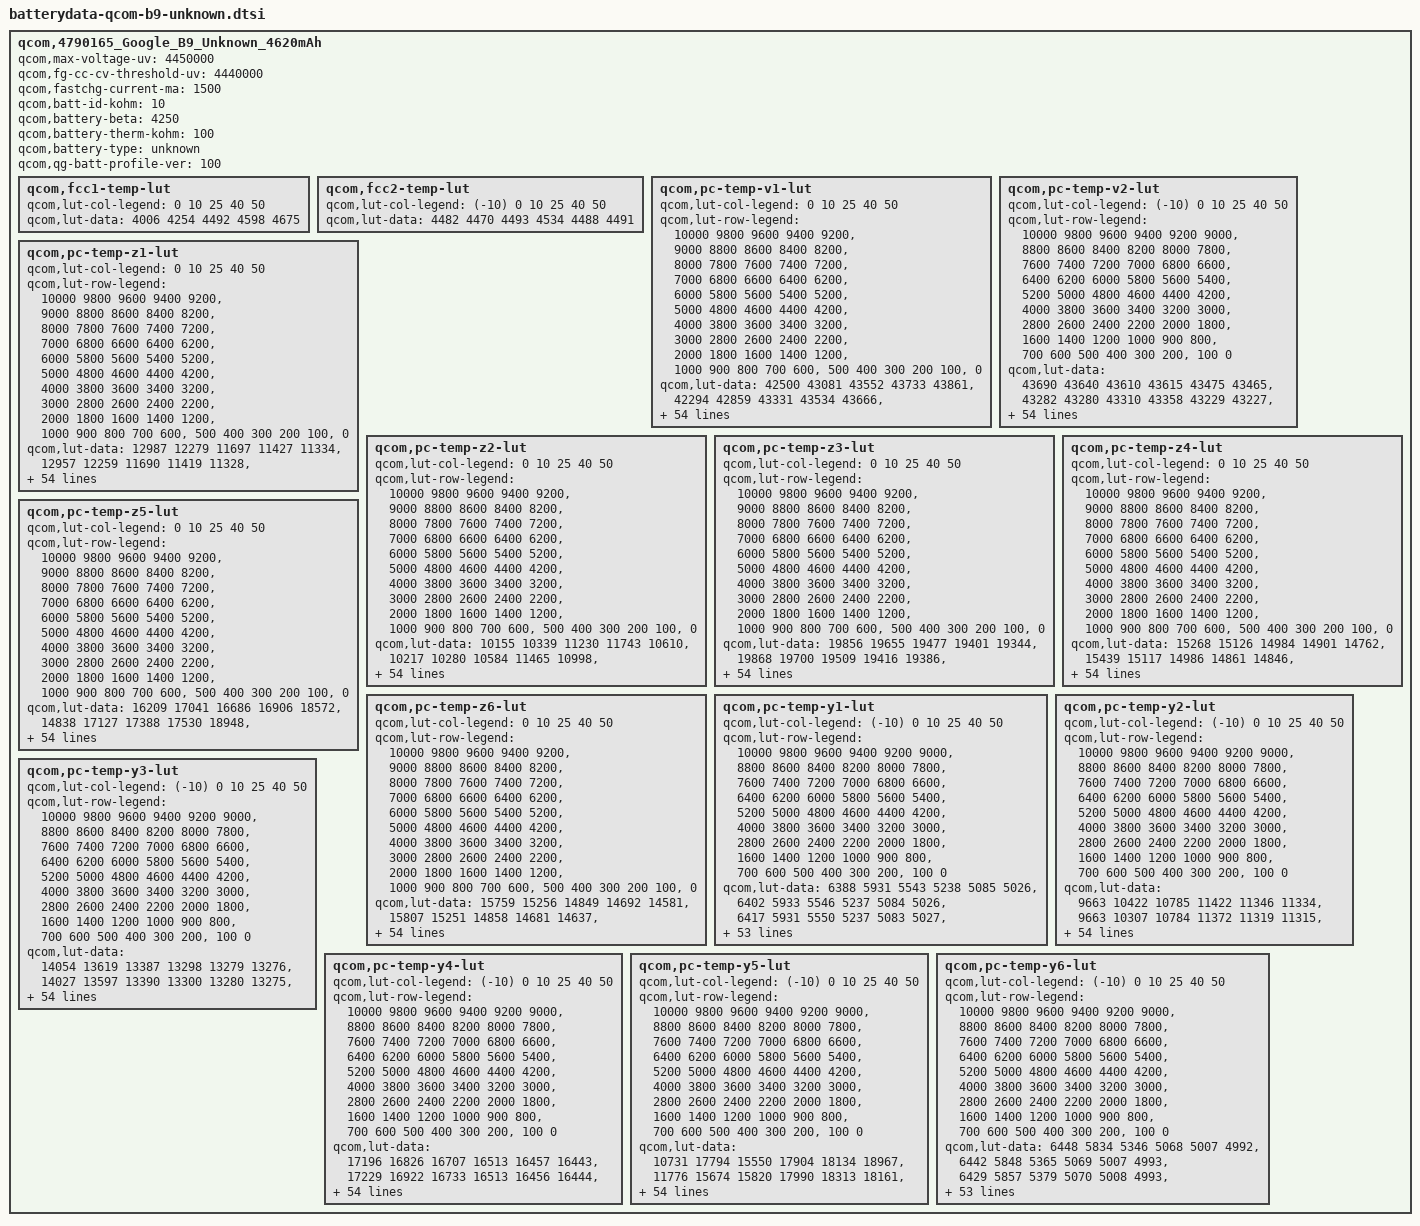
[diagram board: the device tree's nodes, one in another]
// SPDX-License-Identifier: GPL-2.0
qcom,4790165_Google_B9_Unknown_4620mAh {
	/* 4790165_Google_B9lwn_4620mAh_averaged_MasterSlave_Sept25th2020 */
	qcom,max-voltage-uv = <4450000>;
	qcom,fg-cc-cv-threshold-uv = <4440000>;
	qcom,fastchg-current-ma = <1500>;
	qcom,batt-id-kohm = <10>;
	qcom,battery-beta = <4250>;
	qcom,battery-therm-kohm = <100>;
	qcom,battery-type = "unknown";
	qcom,qg-batt-profile-ver = <100>;

	qcom,fcc1-temp-lut {
		qcom,lut-col-legend = <0 10 25 40 50>;
		qcom,lut-data = <4006 4254 4492 4598 4675>;
	};

	qcom,fcc2-temp-lut {
		qcom,lut-col-legend = <(-10) 0 10 25 40 50>;
		qcom,lut-data = <4482 4470 4493 4534 4488 4491>;
	};

	qcom,pc-temp-v1-lut {
		qcom,lut-col-legend = <0 10 25 40 50>;
		qcom,lut-row-legend = <10000 9800 9600 9400 9200>,
			<9000 8800 8600 8400 8200>,
			<8000 7800 7600 7400 7200>,
			<7000 6800 6600 6400 6200>,
			<6000 5800 5600 5400 5200>,
			<5000 4800 4600 4400 4200>,
			<4000 3800 3600 3400 3200>,
			<3000 2800 2600 2400 2200>,
			<2000 1800 1600 1400 1200>,
			<1000 900 800 700 600>,
			<500 400 300 200 100>,
			<0>;
		qcom,lut-data = <42500 43081 43552 43733 43861>,
			<42294 42859 43331 43534 43666>,
			<42088 42638 43108 43326 43467>,
			<41884 42419 42883 43106 43261>,
			<41683 42201 42656 42877 43040>,
			<41486 41985 42426 42646 42808>,
			<41294 41770 42196 42414 42576>,
			<41107 41562 41972 42182 42343>,
			<40927 41360 41752 41952 42111>,
			<40752 41162 41535 41722 41880>,
			<40577 40971 41319 41498 41651>,
			<40395 40786 41108 41281 41427>,
			<40221 40605 40907 41068 41204>,
			<40065 40424 40713 40862 40989>,
			<39926 40247 40527 40661 40781>,
			<39796 40084 40349 40468 40581>,
			<39669 39943 40177 40286 40389>,
			<39549 39803 40007 40109 40206>,
			<39428 39637 39847 39938 40026>,
			<39302 39446 39670 39773 39854>,
			<39172 39255 39425 39590 39680>,
			<39040 39063 39138 39347 39469>,
			<38905 38873 38957 39106 39225>,
			<38767 38743 38862 38947 39026>,
			<38652 38669 38785 38831 38885>,
			<38569 38613 38697 38726 38767>,
			<38500 38558 38607 38622 38656>,
			<38447 38506 38523 38526 38555>,
			<38409 38456 38445 38437 38461>,
			<38377 38407 38374 38354 38371>,
			<38348 38358 38313 38280 38288>,
			<38319 38313 38259 38215 38214>,
			<38292 38275 38210 38156 38146>,
			<38266 38240 38166 38100 38082>,
			<38243 38203 38126 38051 38027>,
			<38217 38169 38085 38000 37970>,
			<38182 38129 38046 37947 37903>,
			<38126 38069 37999 37889 37829>,
			<38050 37977 37925 37816 37748>,
			<37958 37869 37824 37724 37660>,
			<37829 37756 37713 37621 37562>,
			<37689 37628 37592 37505 37447>,
			<37538 37481 37455 37374 37315>,
			<37390 37328 37292 37214 37156>,
			<37272 37207 37164 37087 37025>,
			<37194 37165 37089 37015 36953>,
			<37164 37135 37070 36994 36933>,
			<37137 37110 37051 36982 36919>,
			<37100 37080 37031 36962 36900>,
			<36970 36984 36965 36899 36835>,
			<36659 36700 36688 36611 36546>,
			<36206 36247 36248 36175 36112>,
			<35635 35678 35689 35612 35548>,
			<34872 34910 34929 34848 34784>,
			<33589 33677 33743 33678 33618>,
			<30000 30000 30000 30000 30000>;
	};

	qcom,pc-temp-v2-lut {
		qcom,lut-col-legend = <(-10) 0 10 25 40 50>;
		qcom,lut-row-legend = <10000 9800 9600 9400 9200 9000>,
			<8800 8600 8400 8200 8000 7800>,
			<7600 7400 7200 7000 6800 6600>,
			<6400 6200 6000 5800 5600 5400>,
			<5200 5000 4800 4600 4400 4200>,
			<4000 3800 3600 3400 3200 3000>,
			<2800 2600 2400 2200 2000 1800>,
			<1600 1400 1200 1000 900 800>,
			<700 600 500 400 300 200>,
			<100 0>;
		qcom,lut-data = <43690 43640 43610 43615 43475 43465>,
			<43282 43280 43310 43358 43229 43227>,
			<42909 42951 43029 43108 42989 42993>,
			<42575 42656 42765 42867 42754 42762>,
			<42278 42389 42522 42635 42527 42536>,
			<42001 42145 42286 42405 42302 42312>,
			<41709 41925 42046 42174 42076 42087>,
			<41430 41721 41807 41945 41852 41864>,
			<41260 41509 41577 41720 41631 41644>,
			<41183 41282 41352 41498 41414 41427>,
			<41104 41055 41137 41280 41200 41214>,
			<40861 40843 40942 41068 40992 41006>,
			<40383 40642 40764 40861 40789 40802>,
			<40002 40430 40580 40661 40594 40606>,
			<39796 40192 40387 40466 40404 40415>,
			<39624 39945 40185 40277 40220 40231>,
			<39428 39704 39962 40099 40046 40057>,
			<39217 39465 39714 39929 39884 39894>,
			<39018 39237 39477 39740 39705 39716>,
			<38835 39022 39260 39506 39475 39489>,
			<38668 38819 39057 39265 39226 39245>,
			<38541 38636 38877 39065 39029 39050>,
			<38442 38461 38718 38887 38871 38891>,
			<38358 38319 38572 38734 38734 38753>,
			<38283 38233 38434 38610 38615 38633>,
			<38215 38169 38305 38500 38510 38527>,
			<38151 38114 38189 38397 38413 38428>,
			<38088 38062 38078 38300 38323 38334>,
			<38027 38014 37990 38211 38240 38248>,
			<37967 37968 37938 38129 38164 38169>,
			<37910 37925 37902 38055 38094 38097>,
			<37852 37880 37865 37986 38025 38027>,
			<37793 37834 37823 37924 37960 37965>,
			<37731 37785 37778 37863 37894 37900>,
			<37666 37733 37731 37802 37816 37813>,
			<37597 37679 37682 37740 37724 37699>,
			<37526 37619 37627 37674 37632 37588>,
			<37448 37552 37562 37604 37545 37495>,
			<37367 37475 37486 37528 37459 37407>,
			<37289 37389 37395 37446 37372 37319>,
			<37215 37287 37283 37357 37286 37233>,
			<37141 37177 37166 37252 37191 37139>,
			<37072 37061 37057 37119 37064 37011>,
			<37003 36943 36953 36993 36935 36885>,
			<36925 36853 36856 36890 36867 36821>,
			<36832 36781 36760 36841 36830 36784>,
			<36774 36749 36708 36825 36819 36771>,
			<36706 36713 36654 36806 36804 36756>,
			<36615 36657 36586 36767 36767 36721>,
			<36473 36561 36479 36662 36651 36592>,
			<36240 36345 36280 36341 36320 36250>,
			<35857 35920 35891 35848 35839 35769>,
			<35280 35302 35298 35203 35224 35148>,
			<34439 34440 34481 34308 34376 34298>,
			<33091 33099 33202 32966 33115 33027>,
			<29798 29527 29510 29513 29512 29525>;
	};

	qcom,pc-temp-z1-lut {
		qcom,lut-col-legend = <0 10 25 40 50>;
		qcom,lut-row-legend = <10000 9800 9600 9400 9200>,
			<9000 8800 8600 8400 8200>,
			<8000 7800 7600 7400 7200>,
			<7000 6800 6600 6400 6200>,
			<6000 5800 5600 5400 5200>,
			<5000 4800 4600 4400 4200>,
			<4000 3800 3600 3400 3200>,
			<3000 2800 2600 2400 2200>,
			<2000 1800 1600 1400 1200>,
			<1000 900 800 700 600>,
			<500 400 300 200 100>,
			<0>;
		qcom,lut-data = <12987 12279 11697 11427 11334>,
			<12957 12259 11690 11419 11328>,
			<12955 12253 11684 11412 11324>,
			<12950 12245 11679 11407 11321>,
			<12946 12240 11674 11403 11317>,
			<12933 12235 11670 11400 11314>,
			<12915 12229 11666 11398 11312>,
			<12907 12230 11663 11395 11310>,
			<12903 12243 11660 11393 11309>,
			<12899 12255 11658 11391 11308>,
			<12900 12252 11657 11390 11307>,
			<12916 12240 11656 11390 11307>,
			<12932 12232 11657 11389 11307>,
			<12933 12230 11661 11389 11307>,
			<12921 12229 11664 11390 11308>,
			<12910 12228 11663 11390 11309>,
			<12909 12229 11661 11391 11311>,
			<12907 12230 11661 11393 11312>,
			<12905 12231 11662 11394 11314>,
			<12906 12236 11665 11395 11316>,
			<12914 12242 11669 11397 11318>,
			<12920 12247 11677 11400 11320>,
			<12918 12253 11682 11404 11323>,
			<12913 12259 11686 11409 11327>,
			<12910 12265 11689 11414 11330>,
			<12914 12272 11692 11418 11334>,
			<12920 12277 11695 11423 11337>,
			<12927 12285 11698 11426 11340>,
			<12936 12291 11700 11430 11343>,
			<12948 12289 11703 11432 11346>,
			<12954 12280 11704 11435 11349>,
			<12952 12275 11705 11438 11352>,
			<12949 12280 11706 11442 11354>,
			<12949 12290 11711 11445 11356>,
			<12952 12298 11717 11448 11360>,
			<12955 12305 11720 11450 11363>,
			<12959 12311 11725 11453 11367>,
			<12964 12316 11728 11457 11370>,
			<12971 12320 11729 11460 11373>,
			<12982 12323 11732 11465 11375>,
			<13002 12325 11734 11468 11377>,
			<13010 12326 11737 11472 11381>,
			<12996 12335 11741 11475 11384>,
			<13006 12345 11752 11477 11386>,
			<13013 12328 11752 11482 11388>,
			<13024 12337 11763 11481 11389>,
			<12993 12334 11763 11482 11389>,
			<12977 12332 11765 11481 11389>,
			<12992 12338 11767 11486 11392>,
			<12995 12349 11767 11488 11393>,
			<13041 12362 11773 11493 11400>,
			<13047 12379 11780 11500 11405>,
			<13045 12393 11804 11511 11413>,
			<13078 12427 11826 11525 11424>,
			<13078 12427 11826 11525 11424>,
			<13078 12427 11826 11525 11424>;
	};

	qcom,pc-temp-z2-lut {
		qcom,lut-col-legend = <0 10 25 40 50>;
		qcom,lut-row-legend = <10000 9800 9600 9400 9200>,
			<9000 8800 8600 8400 8200>,
			<8000 7800 7600 7400 7200>,
			<7000 6800 6600 6400 6200>,
			<6000 5800 5600 5400 5200>,
			<5000 4800 4600 4400 4200>,
			<4000 3800 3600 3400 3200>,
			<3000 2800 2600 2400 2200>,
			<2000 1800 1600 1400 1200>,
			<1000 900 800 700 600>,
			<500 400 300 200 100>,
			<0>;
		qcom,lut-data = <10155 10339 11230 11743 10610>,
			<10217 10280 10584 11465 10998>,
			<10211 10251 10518 11289 11357>,
			<10198 10232 10485 11250 11516>,
			<10186 10225 10478 11236 11514>,
			<10174 10233 10493 11215 11514>,
			<10164 10247 10520 11171 11492>,
			<10158 10259 10596 11135 11382>,
			<10158 10271 10750 11139 11278>,
			<10158 10285 10832 11158 11228>,
			<10155 10301 10852 11165 11196>,
			<10141 10321 10862 11109 11206>,
			<10127 10337 10863 11045 11234>,
			<10126 10350 10853 11045 11244>,
			<10141 10362 10849 11072 10952>,
			<10161 10374 10864 11099 10619>,
			<10174 10387 10886 11130 10595>,
			<10186 10400 10871 11151 10604>,
			<10196 10409 10734 11049 10614>,
			<10205 10418 10626 10736 10629>,
			<10214 10422 10622 10596 10646>,
			<10222 10413 10614 10603 10659>,
			<10229 10391 10611 10617 10672>,
			<10235 10381 10618 10674 10690>,
			<10242 10386 10630 10837 10753>,
			<10251 10394 10647 10922 10817>,
			<10261 10401 10672 10820 10760>,
			<10270 10408 10682 10687 10573>,
			<10277 10415 10644 10662 10495>,
			<10284 10420 10595 10658 10495>,
			<10290 10425 10590 10658 10497>,
			<10298 10431 10604 10673 10513>,
			<10306 10439 10622 10700 10555>,
			<10303 10448 10647 10729 10603>,
			<10210 10457 10677 10784 10661>,
			<10100 10467 10702 10829 10719>,
			<10070 10478 10722 10871 10764>,
			<10019 10493 10742 10918 10804>,
			<9963 10513 10774 10953 10835>,
			<9962 10526 10809 10988 10880>,
			<10008 10524 10822 11004 10911>,
			<10012 10519 10818 10977 10883>,
			<9958 10522 10812 10949 10848>,
			<9902 10537 10796 10964 10904>,
			<9900 10660 10818 10928 10872>,
			<9914 11695 10831 10888 10823>,
			<10007 13597 10804 10796 10815>,
			<9902 13310 10796 10818 10793>,
			<9867 16744 10819 10788 10845>,
			<9785 19310 10868 10914 10984>,
			<9717 16266 10976 10890 10714>,
			<9612 13406 10908 10776 10605>,
			<9492 14788 11018 10722 10541>,
			<9380 10829 10954 10649 10484>,
			<9380 10829 10954 10649 10484>,
			<9380 10829 10954 10649 10484>;
	};

	qcom,pc-temp-z3-lut {
		qcom,lut-col-legend = <0 10 25 40 50>;
		qcom,lut-row-legend = <10000 9800 9600 9400 9200>,
			<9000 8800 8600 8400 8200>,
			<8000 7800 7600 7400 7200>,
			<7000 6800 6600 6400 6200>,
			<6000 5800 5600 5400 5200>,
			<5000 4800 4600 4400 4200>,
			<4000 3800 3600 3400 3200>,
			<3000 2800 2600 2400 2200>,
			<2000 1800 1600 1400 1200>,
			<1000 900 800 700 600>,
			<500 400 300 200 100>,
			<0>;
		qcom,lut-data = <19856 19655 19477 19401 19344>,
			<19868 19700 19509 19416 19386>,
			<19868 19700 19510 19425 19398>,
			<19863 19695 19510 19427 19402>,
			<19860 19688 19510 19427 19401>,
			<19861 19679 19499 19425 19399>,
			<19863 19668 19486 19418 19396>,
			<19861 19657 19482 19410 19387>,
			<19851 19644 19482 19407 19379>,
			<19839 19632 19480 19406 19372>,
			<19837 19626 19478 19403 19367>,
			<19850 19622 19475 19394 19365>,
			<19864 19617 19469 19384 19364>,
			<19864 19611 19458 19380 19362>,
			<19835 19604 19449 19377 19350>,
			<19805 19598 19446 19375 19337>,
			<19797 19591 19444 19373 19334>,
			<19793 19586 19442 19371 19332>,
			<19792 19590 19440 19366 19332>,
			<19795 19608 19440 19357 19334>,
			<19807 19623 19447 19354 19336>,
			<19818 19624 19460 19354 19335>,
			<19824 19625 19464 19354 19330>,
			<19829 19626 19447 19358 19328>,
			<19831 19621 19429 19371 19350>,
			<19830 19614 19435 19382 19375>,
			<19827 19609 19458 19389 19374>,
			<19824 19606 19473 19394 19364>,
			<19816 19604 19478 19394 19358>,
			<19804 19605 19480 19393 19357>,
			<19793 19608 19479 19390 19355>,
			<19782 19610 19471 19386 19353>,
			<19771 19608 19463 19380 19350>,
			<19751 19604 19457 19375 19346>,
			<19647 19600 19452 19371 19340>,
			<19529 19595 19448 19368 19336>,
			<19487 19591 19445 19367 19337>,
			<19387 19587 19442 19366 19339>,
			<19282 19582 19440 19365 19339>,
			<19262 19578 19437 19365 19339>,
			<19262 19573 19434 19364 19339>,
			<19262 19568 19430 19361 19337>,
			<19262 19560 19426 19357 19333>,
			<19262 19547 19421 19359 19338>,
			<19262 19507 19409 19354 19338>,
			<19262 19258 19404 19346 19329>,
			<19262 19257 19396 19344 19325>,
			<19262 19257 19396 19336 19322>,
			<19263 19257 19382 19336 19319>,
			<19263 19256 19381 19327 19319>,
			<19264 19257 19373 19332 19336>,
			<19266 19257 19372 19343 19339>,
			<19269 19257 19336 19340 19343>,
			<19273 19259 19328 19347 19346>,
			<19273 19259 19328 19347 19346>,
			<19273 19259 19328 19347 19346>;
	};

	qcom,pc-temp-z4-lut {
		qcom,lut-col-legend = <0 10 25 40 50>;
		qcom,lut-row-legend = <10000 9800 9600 9400 9200>,
			<9000 8800 8600 8400 8200>,
			<8000 7800 7600 7400 7200>,
			<7000 6800 6600 6400 6200>,
			<6000 5800 5600 5400 5200>,
			<5000 4800 4600 4400 4200>,
			<4000 3800 3600 3400 3200>,
			<3000 2800 2600 2400 2200>,
			<2000 1800 1600 1400 1200>,
			<1000 900 800 700 600>,
			<500 400 300 200 100>,
			<0>;
		qcom,lut-data = <15268 15126 14984 14901 14762>,
			<15439 15117 14986 14861 14846>,
			<15395 15080 14955 14826 14807>,
			<15299 15010 14898 14796 14768>,
			<15214 14952 14860 14769 14747>,
			<15149 14910 14840 14753 14731>,
			<15091 14877 14824 14744 14723>,
			<15043 14859 14804 14738 14719>,
			<15003 14850 14780 14728 14716>,
			<14970 14843 14763 14716 14710>,
			<14945 14831 14750 14708 14703>,
			<14921 14817 14740 14704 14694>,
			<14904 14810 14736 14701 14684>,
			<14901 14812 14734 14695 14678>,
			<14904 14815 14732 14687 14682>,
			<14908 14815 14726 14679 14686>,
			<14904 14799 14717 14671 14682>,
			<14885 14781 14715 14666 14674>,
			<14867 14784 14722 14668 14670>,
			<14863 14812 14734 14682 14672>,
			<14862 14850 14798 14703 14677>,
			<14863 14905 14923 14784 14708>,
			<14881 14976 14968 14874 14801>,
			<14924 15006 14955 14878 14845>,
			<14952 14987 14933 14845 14808>,
			<14953 14956 14901 14812 14761>,
			<14953 14929 14854 14784 14745>,
			<14950 14903 14819 14759 14737>,
			<14939 14880 14797 14741 14728>,
			<14919 14862 14782 14727 14715>,
			<14901 14846 14776 14718 14703>,
			<14885 14834 14773 14711 14693>,
			<14871 14826 14771 14706 14686>,
			<14870 14820 14772 14706 14683>,
			<14955 14814 14773 14709 14686>,
			<15057 14809 14774 14713 14690>,
			<15091 14805 14775 14721 14700>,
			<15178 14805 14776 14731 14716>,
			<15271 14809 14780 14737 14720>,
			<15283 14812 14787 14742 14720>,
			<15277 14805 14788 14744 14719>,
			<15268 14789 14774 14736 14715>,
			<15246 14780 14762 14730 14710>,
			<15180 14770 14757 14729 14711>,
			<15109 14733 14729 14720 14706>,
			<15097 14971 14706 14698 14690>,
			<15090 14962 14694 14684 14678>,
			<15078 14954 14680 14669 14660>,
			<15071 14943 14678 14653 14643>,
			<15070 14945 14682 14668 14648>,
			<15089 14962 14715 14690 14658>,
			<15114 14971 14720 14681 14657>,
			<15135 14976 14759 14684 14654>,
			<15165 14984 14769 14675 14651>,
			<15165 14984 14769 14675 14651>,
			<15165 14984 14769 14675 14651>;
	};

	qcom,pc-temp-z5-lut {
		qcom,lut-col-legend = <0 10 25 40 50>;
		qcom,lut-row-legend = <10000 9800 9600 9400 9200>,
			<9000 8800 8600 8400 8200>,
			<8000 7800 7600 7400 7200>,
			<7000 6800 6600 6400 6200>,
			<6000 5800 5600 5400 5200>,
			<5000 4800 4600 4400 4200>,
			<4000 3800 3600 3400 3200>,
			<3000 2800 2600 2400 2200>,
			<2000 1800 1600 1400 1200>,
			<1000 900 800 700 600>,
			<500 400 300 200 100>,
			<0>;
		qcom,lut-data = <16209 17041 16686 16906 18572>,
			<14838 17127 17388 17530 18948>,
			<15000 17388 17824 18296 19883>,
			<15360 17894 18378 19376 20913>,
			<15713 18505 18757 20735 22224>,
			<16103 19501 18976 21217 23444>,
			<16584 20484 19143 21035 23591>,
			<17057 20737 19445 20823 22876>,
			<17466 20717 20128 21228 22143>,
			<17934 20703 20785 22453 21833>,
			<18707 21029 21670 22955 21604>,
			<20606 21920 22489 22258 21946>,
			<22451 22508 22443 21427 23396>,
			<22612 22582 21736 21649 24114>,
			<21203 22616 21296 22755 22033>,
			<19803 22726 21676 23871 19597>,
			<19757 23186 22533 25132 19483>,
			<20626 24046 23474 26215 20150>,
			<21979 26539 24856 25818 21066>,
			<24138 33489 26455 23514 22719>,
			<27949 38471 28307 21778 24309>,
			<31641 37869 30270 20328 23134>,
			<34368 35817 30521 18792 18250>,
			<36861 33539 24955 17839 15901>,
			<38066 30500 19154 17110 16990>,
			<37735 27526 18953 16843 18249>,
			<36831 26420 20206 17568 18292>,
			<35730 25959 21832 18943 18094>,
			<34183 25724 24378 20411 18069>,
			<32268 26323 27230 22226 19115>,
			<30662 28486 29031 23945 20756>,
			<29362 30498 30343 25559 22426>,
			<28208 31817 31325 26991 24234>,
			<27101 32976 32163 27984 25004>,
			<23895 33697 32802 29004 25258>,
			<20523 34252 32885 29444 25384>,
			<19361 34619 32474 28880 25284>,
			<15762 34550 31811 27818 24939>,
			<11926 33951 30655 26753 24479>,
			<11257 33270 28945 25387 23665>,
			<11266 32544 27772 24137 22725>,
			<11274 31491 27160 23167 21751>,
			<11279 30141 26310 22402 20924>,
			<11371 28447 24457 21886 21009>,
			<11463 27177 24915 21215 20910>,
			<11420 11532 25461 21100 19671>,
			<11390 11504 23907 22001 19735>,
			<11350 11472 24958 21410 21293>,
			<11362 11448 22746 24520 25076>,
			<11427 11481 21980 19837 22198>,
			<11397 11504 17600 16823 21107>,
			<11324 11400 16799 17847 20967>,
			<11238 11305 13801 16919 21115>,
			<11144 11240 13251 17661 21321>,
			<11144 11240 13251 17661 21321>,
			<11144 11240 13251 17661 21321>;
	};

	qcom,pc-temp-z6-lut {
		qcom,lut-col-legend = <0 10 25 40 50>;
		qcom,lut-row-legend = <10000 9800 9600 9400 9200>,
			<9000 8800 8600 8400 8200>,
			<8000 7800 7600 7400 7200>,
			<7000 6800 6600 6400 6200>,
			<6000 5800 5600 5400 5200>,
			<5000 4800 4600 4400 4200>,
			<4000 3800 3600 3400 3200>,
			<3000 2800 2600 2400 2200>,
			<2000 1800 1600 1400 1200>,
			<1000 900 800 700 600>,
			<500 400 300 200 100>,
			<0>;
		qcom,lut-data = <15759 15256 14849 14692 14581>,
			<15807 15251 14858 14681 14637>,
			<15776 15225 14843 14669 14627>,
			<15709 15174 14814 14657 14615>,
			<15650 15132 14791 14644 14606>,
			<15608 15101 14775 14634 14597>,
			<15570 15076 14760 14626 14590>,
			<15538 15059 14748 14619 14583>,
			<15505 15047 14737 14612 14577>,
			<15479 15038 14727 14606 14571>,
			<15471 15029 14720 14600 14565>,
			<15471 15020 14713 14593 14560>,
			<15470 15013 14707 14586 14555>,
			<15467 15009 14701 14581 14550>,
			<15458 15007 14695 14576 14545>,
			<15448 15002 14690 14572 14541>,
			<15440 14993 14685 14567 14536>,
			<15433 14984 14685 14564 14532>,
			<15428 14987 14687 14564 14530>,
			<15429 15010 14692 14566 14532>,
			<15436 15038 14724 14570 14536>,
			<15445 15069 14787 14605 14550>,
			<15460 15103 14808 14647 14589>,
			<15480 15116 14796 14651 14607>,
			<15494 15108 14780 14645 14604>,
			<15498 15093 14770 14638 14598>,
			<15501 15081 14763 14631 14591>,
			<15502 15069 14757 14623 14583>,
			<15496 15060 14752 14616 14576>,
			<15484 15055 14748 14610 14570>,
			<15473 15051 14744 14605 14564>,
			<15465 15049 14740 14599 14559>,
			<15457 15048 14737 14594 14554>,
			<15449 15047 14735 14593 14551>,
			<15438 15046 14734 14592 14550>,
			<15428 15045 14734 14592 14549>,
			<15424 15044 14734 14595 14553>,
			<15420 15045 14734 14599 14561>,
			<15417 15050 14736 14602 14564>,
			<15419 15053 14739 14605 14564>,
			<15430 15051 14740 14606 14565>,
			<15435 15047 14734 14602 14562>,
			<15434 15045 14729 14598 14559>,
			<15422 15043 14727 14599 14562>,
			<15401 15021 14712 14593 14560>,
			<15394 15003 14703 14580 14549>,
			<15391 15002 14695 14573 14541>,
			<15386 15001 14689 14563 14531>,
			<15389 15002 14684 14556 14523>,
			<15400 15008 14687 14558 14525>,
			<15421 15023 14700 14572 14541>,
			<15447 15035 14706 14576 14543>,
			<15479 15050 14709 14578 14546>,
			<15527 15075 14717 14582 14549>,
			<15527 15075 14717 14582 14549>,
			<15527 15075 14717 14582 14549>;
	};

	qcom,pc-temp-y1-lut {
		qcom,lut-col-legend = <(-10) 0 10 25 40 50>;
		qcom,lut-row-legend = <10000 9800 9600 9400 9200 9000>,
			<8800 8600 8400 8200 8000 7800>,
			<7600 7400 7200 7000 6800 6600>,
			<6400 6200 6000 5800 5600 5400>,
			<5200 5000 4800 4600 4400 4200>,
			<4000 3800 3600 3400 3200 3000>,
			<2800 2600 2400 2200 2000 1800>,
			<1600 1400 1200 1000 900 800>,
			<700 600 500 400 300 200>,
			<100 0>;
		qcom,lut-data = <6388 5931 5543 5238 5085 5026>,
			<6402 5933 5546 5237 5084 5026>,
			<6417 5931 5550 5237 5083 5027>,
			<6432 5929 5554 5236 5081 5027>,
			<6443 5926 5558 5236 5080 5027>,
			<6448 5924 5560 5236 5079 5026>,
			<6446 5921 5561 5235 5078 5026>,
			<6442 5916 5561 5235 5076 5025>,
			<6439 5914 5563 5235 5076 5024>,
			<6440 5920 5566 5235 5075 5025>,
			<6442 5929 5568 5234 5075 5025>,
			<6450 5936 5569 5234 5074 5025>,
			<6467 5944 5569 5233 5074 5025>,
			<6475 5947 5569 5233 5074 5025>,
			<6468 5940 5566 5233 5074 5025>,
			<6459 5931 5562 5232 5074 5025>,
			<6461 5931 5563 5232 5074 5025>,
			<6468 5941 5567 5233 5075 5026>,
			<6472 5949 5570 5234 5076 5026>,
			<6472 5947 5569 5236 5077 5027>,
			<6472 5940 5567 5239 5078 5028>,
			<6471 5938 5567 5242 5079 5029>,
			<6463 5936 5571 5245 5080 5030>,
			<6455 5935 5574 5247 5082 5031>,
			<6448 5935 5578 5248 5084 5032>,
			<6439 5936 5584 5249 5086 5034>,
			<6436 5937 5587 5251 5088 5036>,
			<6444 5941 5586 5255 5089 5037>,
			<6454 5946 5584 5258 5091 5038>,
			<6459 5946 5581 5260 5093 5040>,
			<6461 5941 5578 5262 5096 5042>,
			<6461 5936 5577 5264 5098 5044>,
			<6456 5934 5578 5264 5101 5047>,
			<6451 5933 5579 5265 5104 5049>,
			<6451 5933 5578 5266 5107 5051>,
			<6452 5936 5578 5268 5110 5053>,
			<6452 5940 5579 5270 5113 5054>,
			<6460 5941 5584 5275 5114 5055>,
			<6478 5942 5591 5280 5114 5056>,
			<6483 5942 5594 5281 5115 5058>,
			<6464 5940 5592 5280 5116 5059>,
			<6444 5937 5590 5282 5117 5061>,
			<6447 5938 5591 5287 5119 5063>,
			<6459 5941 5594 5290 5122 5065>,
			<6471 5948 5602 5292 5125 5067>,
			<6496 5959 5607 5298 5127 5068>,
			<6531 5968 5607 5301 5128 5069>,
			<6541 5978 5608 5296 5128 5069>,
			<6551 5989 5619 5297 5128 5068>,
			<6583 5990 5627 5302 5127 5068>,
			<6625 5993 5633 5308 5130 5070>,
			<6663 6024 5658 5310 5140 5075>,
			<6744 6065 5661 5329 5143 5080>,
			<6757 6126 5697 5348 5155 5087>,
			<6757 6126 5697 5348 5155 5087>,
			<6757 6126 5697 5348 5155 5087>;
	};

	qcom,pc-temp-y2-lut {
		qcom,lut-col-legend = <(-10) 0 10 25 40 50>;
		qcom,lut-row-legend = <10000 9800 9600 9400 9200 9000>,
			<8800 8600 8400 8200 8000 7800>,
			<7600 7400 7200 7000 6800 6600>,
			<6400 6200 6000 5800 5600 5400>,
			<5200 5000 4800 4600 4400 4200>,
			<4000 3800 3600 3400 3200 3000>,
			<2800 2600 2400 2200 2000 1800>,
			<1600 1400 1200 1000 900 800>,
			<700 600 500 400 300 200>,
			<100 0>;
		qcom,lut-data = <9663 10422 10785 11422 11346 11334>,
			<9663 10307 10784 11372 11319 11315>,
			<9664 10254 10785 11319 11289 11282>,
			<9665 10250 10789 11270 11259 11241>,
			<9665 10280 10793 11226 11237 11203>,
			<9665 10330 10796 11193 11226 11175>,
			<9665 10436 10799 11166 11224 11157>,
			<9665 10597 10803 11145 11220 11136>,
			<9665 10650 10813 11140 11220 11122>,
			<9666 10584 10866 11146 11222 11118>,
			<9667 10514 10918 11151 11225 11124>,
			<9667 10567 10923 11153 11231 11141>,
			<9666 10763 10920 11157 11240 11174>,
			<9665 10862 10923 11165 11253 11207>,
			<9665 10435 11005 11205 11275 11242>,
			<9665 9837 11112 11261 11310 11284>,
			<9665 9708 11144 11312 11366 11353>,
			<9665 9696 11157 11366 11465 11467>,
			<9665 9690 11166 11391 11521 11527>,
			<9665 9684 11175 11398 11507 11494>,
			<9665 9680 11185 11402 11481 11433>,
			<9664 9678 11194 11412 11467 11407>,
			<9664 9676 11205 11436 11438 11398>,
			<9664 9674 11211 11459 11417 11404>,
			<9664 9673 11164 11481 11431 11434>,
			<9664 9671 11066 11506 11472 11479>,
			<9664 9670 11034 11533 11525 11510>,
			<9663 9668 11046 11563 11612 11529>,
			<9663 9667 11057 11584 11698 11549>,
			<9663 9666 11044 11596 11742 11582>,
			<9663 9665 10983 11605 11772 11628>,
			<9663 9664 10876 11614 11797 11674>,
			<9663 9663 10446 11626 11823 11745>,
			<9663 9663 9950 11633 11841 11814>,
			<9663 9662 9797 11614 11834 11797>,
			<9663 9662 9729 11571 11782 11676>,
			<9663 9661 9697 11536 11719 11598>,
			<9662 9661 9686 11503 11644 11604>,
			<9662 9661 9680 11467 11570 11615>,
			<9662 9661 9675 11426 11549 11614>,
			<9662 9660 9670 11378 11545 11590>,
			<9661 9660 9667 11321 11542 11562>,
			<9661 9660 9664 11239 11513 11554>,
			<9660 9660 9663 11142 11466 11544>,
			<9659 9659 9661 11022 11412 11406>,
			<9657 9658 9660 10952 11371 11275>,
			<9656 9658 9660 10972 11379 11247>,
			<9655 9658 9661 11065 11402 11291>,
			<9654 9657 9661 11094 11461 11375>,
			<9653 9657 9660 11090 11451 11323>,
			<9651 9655 9659 10993 11371 11220>,
			<9650 9653 9658 10877 11241 11172>,
			<9650 9651 9655 10731 11225 11122>,
			<9649 9650 9653 10568 11131 11013>,
			<9649 9650 9653 10568 11131 11013>,
			<9649 9650 9653 10568 11131 11013>;
	};

	qcom,pc-temp-y3-lut {
		qcom,lut-col-legend = <(-10) 0 10 25 40 50>;
		qcom,lut-row-legend = <10000 9800 9600 9400 9200 9000>,
			<8800 8600 8400 8200 8000 7800>,
			<7600 7400 7200 7000 6800 6600>,
			<6400 6200 6000 5800 5600 5400>,
			<5200 5000 4800 4600 4400 4200>,
			<4000 3800 3600 3400 3200 3000>,
			<2800 2600 2400 2200 2000 1800>,
			<1600 1400 1200 1000 900 800>,
			<700 600 500 400 300 200>,
			<100 0>;
		qcom,lut-data = <14054 13619 13387 13298 13279 13276>,
			<14027 13597 13390 13300 13280 13275>,
			<13995 13583 13395 13302 13282 13275>,
			<13958 13575 13399 13304 13283 13276>,
			<13918 13572 13404 13306 13284 13276>,
			<13874 13571 13406 13308 13285 13277>,
			<13815 13576 13406 13309 13286 13279>,
			<13752 13586 13407 13310 13287 13280>,
			<13734 13587 13408 13311 13288 13282>,
			<13756 13538 13418 13311 13288 13284>,
			<13779 13484 13428 13312 13289 13286>,
			<13760 13482 13421 13314 13289 13286>,
			<13696 13493 13396 13316 13291 13286>,
			<13664 13498 13385 13317 13292 13286>,
			<13668 13496 13386 13316 13292 13286>,
			<13674 13491 13387 13316 13293 13287>,
			<13673 13485 13386 13315 13293 13288>,
			<13663 13476 13377 13312 13294 13289>,
			<13657 13469 13368 13310 13295 13290>,
			<13658 13469 13362 13308 13291 13286>,
			<13659 13469 13356 13306 13285 13280>,
			<13663 13466 13351 13304 13282 13277>,
			<13674 13445 13345 13301 13281 13277>,
			<13690 13425 13341 13300 13280 13276>,
			<13706 13431 13339 13300 13279 13276>,
			<13726 13457 13337 13299 13279 13276>,
			<13749 13484 13334 13299 13279 13276>,
			<13778 13512 13325 13298 13279 13275>,
			<13809 13543 13317 13297 13280 13274>,
			<13841 13575 13319 13297 13280 13274>,
			<13873 13609 13327 13297 13281 13275>,
			<13905 13644 13334 13298 13281 13275>,
			<13934 13681 13338 13298 13282 13276>,
			<13963 13719 13341 13299 13283 13277>,
			<13991 13761 13349 13299 13283 13277>,
			<14020 13810 13366 13299 13282 13275>,
			<14048 13856 13386 13299 13280 13274>,
			<14078 13892 13411 13299 13279 13274>,
			<14109 13924 13441 13299 13279 13274>,
			<14141 13951 13477 13300 13278 13274>,
			<14171 13974 13519 13302 13278 13275>,
			<14207 13996 13569 13304 13278 13275>,
			<14252 14024 13633 13305 13278 13275>,
			<14317 14058 13709 13307 13278 13275>,
			<14452 14111 13795 13310 13280 13277>,
			<14722 14192 13874 13319 13285 13280>,
			<14981 14259 13903 13321 13290 13282>,
			<15104 14299 13838 13321 13293 13286>,
			<15195 14287 13787 13326 13295 13288>,
			<15827 14413 13865 13328 13295 13287>,
			<16886 14737 13950 13322 13287 13282>,
			<19031 15385 14059 13328 13288 13283>,
			<23585 16782 14387 13337 13294 13285>,
			<35055 19876 15170 13358 13298 13289>,
			<35055 19876 15170 13358 13298 13289>,
			<35055 19876 15170 13358 13298 13289>;
	};

	qcom,pc-temp-y4-lut {
		qcom,lut-col-legend = <(-10) 0 10 25 40 50>;
		qcom,lut-row-legend = <10000 9800 9600 9400 9200 9000>,
			<8800 8600 8400 8200 8000 7800>,
			<7600 7400 7200 7000 6800 6600>,
			<6400 6200 6000 5800 5600 5400>,
			<5200 5000 4800 4600 4400 4200>,
			<4000 3800 3600 3400 3200 3000>,
			<2800 2600 2400 2200 2000 1800>,
			<1600 1400 1200 1000 900 800>,
			<700 600 500 400 300 200>,
			<100 0>;
		qcom,lut-data = <17196 16826 16707 16513 16457 16443>,
			<17229 16922 16733 16513 16456 16444>,
			<17262 17005 16774 16514 16455 16445>,
			<17293 17072 16819 16516 16455 16446>,
			<17320 17116 16856 16518 16456 16447>,
			<17341 17136 16874 16520 16457 16448>,
			<17355 17120 16873 16522 16458 16449>,
			<17366 17085 16869 16525 16461 16450>,
			<17382 17076 16863 16529 16464 16450>,
			<17419 17164 16850 16534 16469 16452>,
			<17450 17258 16840 16539 16474 16454>,
			<17393 17245 16871 16545 16479 16458>,
			<17205 17165 16963 16552 16484 16465>,
			<17080 17104 17005 16562 16489 16472>,
			<17044 17083 16991 16575 16497 16479>,
			<17018 17065 16964 16592 16508 16487>,
			<16975 17032 16928 16615 16523 16498>,
			<16915 16971 16869 16644 16547 16515>,
			<16867 16903 16812 16654 16559 16524>,
			<16838 16832 16763 16619 16539 16511>,
			<16817 16762 16719 16567 16500 16486>,
			<16813 16724 16688 16536 16480 16469>,
			<16815 16701 16666 16511 16468 16456>,
			<16816 16688 16644 16501 16462 16449>,
			<16815 16685 16614 16502 16463 16450>,
			<16812 16684 16582 16504 16468 16453>,
			<16810 16685 16565 16506 16474 16458>,
			<16813 16686 16556 16511 16481 16466>,
			<16816 16687 16551 16517 16489 16476>,
			<16817 16691 16553 16523 16499 16485>,
			<16816 16699 16561 16529 16510 16494>,
			<16816 16707 16574 16533 16517 16502>,
			<16818 16716 16605 16536 16521 16511>,
			<16820 16724 16643 16538 16523 16517>,
			<16820 16731 16671 16534 16519 16512>,
			<16819 16737 16697 16525 16500 16487>,
			<16819 16741 16712 16518 16483 16468>,
			<16821 16742 16719 16513 16474 16462>,
			<16826 16743 16723 16510 16467 16458>,
			<16833 16742 16724 16514 16467 16458>,
			<16845 16732 16720 16526 16472 16461>,
			<16860 16719 16717 16535 16476 16462>,
			<16876 16711 16719 16541 16473 16457>,
			<16896 16706 16727 16547 16467 16450>,
			<16947 16710 16769 16555 16469 16451>,
			<17052 16734 16854 16584 16480 16461>,
			<17143 16763 16905 16587 16495 16479>,
			<17155 16782 16883 16583 16506 16493>,
			<17101 16779 16861 16610 16516 16507>,
			<17276 16808 16911 16624 16515 16497>,
			<17555 16883 16938 16583 16477 16456>,
			<18151 17008 16924 16575 16472 16453>,
			<20010 17447 17006 16601 16476 16457>,
			<29346 19432 17537 16641 16496 16471>,
			<29346 19432 17537 16641 16496 16471>,
			<29346 19432 17537 16641 16496 16471>;
	};

	qcom,pc-temp-y5-lut {
		qcom,lut-col-legend = <(-10) 0 10 25 40 50>;
		qcom,lut-row-legend = <10000 9800 9600 9400 9200 9000>,
			<8800 8600 8400 8200 8000 7800>,
			<7600 7400 7200 7000 6800 6600>,
			<6400 6200 6000 5800 5600 5400>,
			<5200 5000 4800 4600 4400 4200>,
			<4000 3800 3600 3400 3200 3000>,
			<2800 2600 2400 2200 2000 1800>,
			<1600 1400 1200 1000 900 800>,
			<700 600 500 400 300 200>,
			<100 0>;
		qcom,lut-data = <10731 17794 15550 17904 18134 18967>,
			<11776 15674 15820 17990 18313 18161>,
			<12581 14728 16201 17951 18382 17627>,
			<13153 14675 16609 17825 18362 17297>,
			<13504 15237 16958 17646 18275 17105>,
			<13640 16135 17161 17451 18144 16984>,
			<13455 17884 17213 17168 17923 17197>,
			<13041 20398 17241 16752 17563 17838>,
			<13141 21142 17342 16362 17149 18121>,
			<16777 18844 17979 15961 16577 18412>,
			<20509 16390 18584 15662 16046 18542>,
			<19592 17212 18303 15554 15807 17990>,
			<15804 20686 17377 15491 15771 16973>,
			<13940 22499 16989 15383 15791 16284>,
			<14558 20698 18337 15079 15406 15894>,
			<15363 18206 20247 14819 14909 15643>,
			<15444 17740 21135 14887 14890 15633>,
			<15140 17816 21651 15258 15074 15707>,
			<14698 17936 22055 15896 15379 15962>,
			<13876 18270 22428 18430 16857 17126>,
			<12855 18758 22730 21129 18925 18673>,
			<12419 18598 22921 21528 19371 19290>,
			<12233 15517 23044 21462 19085 19727>,
			<12144 12623 23209 21351 18723 19950>,
			<12188 12464 23935 21272 18217 19597>,
			<12312 12596 25101 21180 17499 18799>,
			<12368 12725 25035 20962 17257 17945>,
			<12405 12887 19935 20454 17367 16834>,
			<12462 13076 14965 20147 17562 16033>,
			<12566 13238 15028 20326 17829 16066>,
			<12799 13431 16168 20783 18269 16380>,
			<13006 13568 16639 21498 18836 16794>,
			<13154 13678 15640 22992 19851 17592>,
			<13267 13828 14436 24062 20855 18492>,
			<13299 13989 14274 24151 21134 18923>,
			<13312 14276 14329 24126 21238 19187>,
			<13317 14518 14418 23874 21274 19340>,
			<13169 14617 14773 22378 20685 19386>,
			<12849 14695 15222 20660 19481 19349>,
			<12640 14722 15246 19706 18505 19148>,
			<12498 14686 14849 18974 17594 18508>,
			<12418 14604 14545 18305 17012 18049>,
			<12536 14231 14534 17653 16980 18614>,
			<12794 13489 14534 17134 17116 19502>,
			<12796 13396 14323 16686 16989 19074>,
			<12664 13438 14051 16298 16684 17735>,
			<12415 13561 13995 16693 16895 16788>,
			<12371 13732 14515 17906 17689 17571>,
			<12396 13815 15613 18671 18594 18629>,
			<11772 14115 16211 19168 18998 18687>,
			<10989 13354 16405 18569 18001 19590>,
			<10096 11941 15150 19334 19339 20304>,
			<9393 10664 12878 18368 22164 20824>,
			<8988 9583 10888 18894 24164 24660>,
			<8988 9583 10888 18894 24164 24660>,
			<8988 9583 10888 18894 24164 24660>;
	};

	qcom,pc-temp-y6-lut {
		qcom,lut-col-legend = <(-10) 0 10 25 40 50>;
		qcom,lut-row-legend = <10000 9800 9600 9400 9200 9000>,
			<8800 8600 8400 8200 8000 7800>,
			<7600 7400 7200 7000 6800 6600>,
			<6400 6200 6000 5800 5600 5400>,
			<5200 5000 4800 4600 4400 4200>,
			<4000 3800 3600 3400 3200 3000>,
			<2800 2600 2400 2200 2000 1800>,
			<1600 1400 1200 1000 900 800>,
			<700 600 500 400 300 200>,
			<100 0>;
		qcom,lut-data = <6448 5834 5346 5068 5007 4992>,
			<6442 5848 5365 5069 5007 4993>,
			<6429 5857 5379 5070 5008 4993>,
			<6409 5862 5389 5072 5009 4994>,
			<6385 5865 5396 5073 5010 4995>,
			<6357 5866 5398 5074 5011 4996>,
			<6316 5865 5395 5075 5012 4998>,
			<6270 5860 5388 5076 5013 4999>,
			<6257 5855 5385 5077 5014 5001>,
			<6281 5849 5386 5079 5016 5002>,
			<6306 5842 5388 5081 5018 5004>,
			<6276 5836 5392 5083 5020 5006>,
			<6176 5828 5400 5086 5022 5008>,
			<6121 5818 5403 5089 5024 5010>,
			<6116 5797 5400 5093 5027 5012>,
			<6113 5770 5394 5097 5030 5014>,
			<6102 5749 5383 5102 5035 5018>,
			<6074 5730 5362 5108 5042 5024>,
			<6056 5715 5341 5110 5046 5027>,
			<6055 5701 5324 5099 5037 5021>,
			<6054 5690 5309 5083 5022 5009>,
			<6055 5681 5300 5072 5014 5002>,
			<6065 5671 5294 5064 5009 4997>,
			<6078 5666 5290 5060 5007 4995>,
			<6090 5674 5286 5061 5007 4995>,
			<6102 5702 5283 5062 5009 4997>,
			<6118 5731 5282 5063 5010 4998>,
			<6141 5759 5282 5065 5013 5000>,
			<6167 5788 5284 5067 5016 5002>,
			<6192 5818 5292 5069 5019 5005>,
			<6218 5850 5314 5072 5023 5008>,
			<6242 5884 5338 5075 5026 5011>,
			<6265 5917 5361 5078 5028 5014>,
			<6287 5951 5387 5079 5029 5017>,
			<6309 5988 5418 5079 5028 5015>,
			<6333 6029 5457 5078 5022 5007>,
			<6357 6067 5499 5078 5017 5001>,
			<6384 6098 5544 5078 5014 5000>,
			<6413 6125 5591 5078 5012 4999>,
			<6442 6147 5640 5081 5012 4999>,
			<6469 6163 5691 5089 5013 5000>,
			<6502 6179 5747 5096 5015 5001>,
			<6543 6201 5811 5103 5014 5000>,
			<6604 6231 5885 5112 5013 4998>,
			<6739 6279 5975 5124 5015 5000>,
			<7017 6354 6069 5147 5023 5006>,
			<7278 6419 6111 5147 5031 5012>,
			<7383 6458 6048 5140 5036 5019>,
			<7449 6451 5996 5153 5040 5025>,
			<8017 6564 6079 5159 5039 5021>,
			<8931 6868 6162 5146 5024 5006>,
			<10732 7442 6257 5157 5024 5006>,
			<14556 8649 6572 5188 5031 5010>,
			<24964 11475 7351 5238 5040 5018>,
			<24964 11475 7351 5238 5040 5018>,
			<24964 11475 7351 5238 5040 5018>;
	};

};
